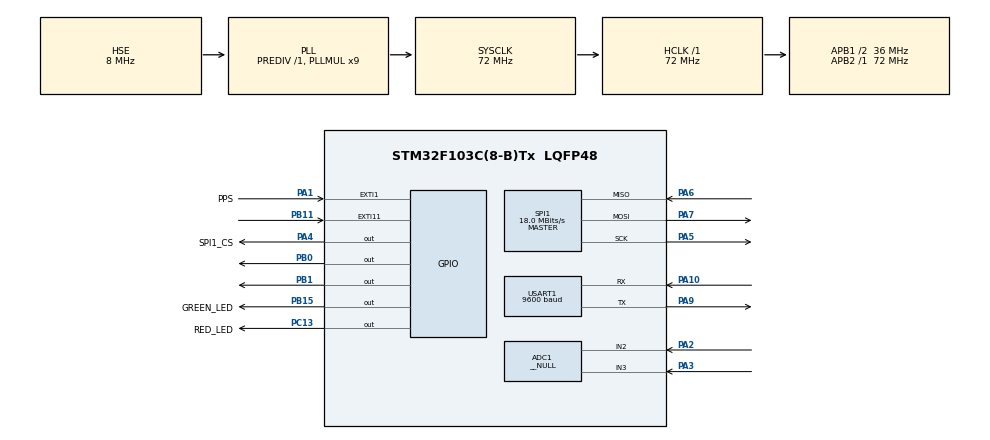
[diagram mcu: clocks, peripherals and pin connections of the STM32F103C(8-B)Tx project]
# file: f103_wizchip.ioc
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ADC1.Channel-0\#ChannelRegularConversion=ADC_CHANNEL_2
ADC1.ContinuousConvMode=DISABLE
ADC1.ExternalTrigConv=ADC_EXTERNALTRIGCONV_EXT_IT11
ADC1.InjNumberOfConversion=0
ADC1.Mode=__NULL
ADC1.NbrOfConversion=1
ADC1.NbrOfConversionFlag=1
ADC1.Rank-0\#ChannelRegularConversion=1
ADC1.SamplingTime-0\#ChannelRegularConversion=ADC_SAMPLETIME_1CYCLE_5
ADC1.master=1
ADC2.Channel-0\#ChannelRegularConversion=ADC_CHANNEL_3
ADC2.NbrOfConversionFlag=1
ADC2.Rank-0\#ChannelRegularConversion=1
ADC2.SamplingTime-0\#ChannelRegularConversion=ADC_SAMPLETIME_1CYCLE_5
Dma.ADC1.0.Direction=DMA_PERIPH_TO_MEMORY
Dma.ADC1.0.Instance=DMA1_Channel1
Dma.ADC1.0.MemDataAlignment=DMA_MDATAALIGN_HALFWORD
Dma.ADC1.0.MemInc=DMA_MINC_ENABLE
Dma.ADC1.0.Mode=DMA_CIRCULAR
Dma.ADC1.0.PeriphDataAlignment=DMA_PDATAALIGN_HALFWORD
Dma.ADC1.0.PeriphInc=DMA_PINC_DISABLE
Dma.ADC1.0.Priority=DMA_PRIORITY_VERY_HIGH
Dma.Request0=ADC1
Mcu.Family=STM32F1
Mcu.Name=STM32F103C(8-B)Tx
Mcu.Package=LQFP48
NVIC.DMA1_Channel1_IRQn=true\:0\:0\:false\:false\:true\:false
NVIC.EXTI1_IRQn=true\:0\:0\:false\:false\:true\:true
NVIC.PriorityGroup=NVIC_PRIORITYGROUP_4
PA1.GPIO_Label=PPS
PA1.GPIO_ModeDefaultEXTI=GPIO_MODE_IT_RISING
PA1.GPIO_PuPd=GPIO_NOPULL
PA1.Signal=GPXTI1
PA10.Mode=Asynchronous
PA10.Signal=USART1_RX
PA13.Mode=Serial_Wire
PA13.Signal=SYS_JTMS-SWDIO
PA14.Mode=Serial_Wire
PA14.Signal=SYS_JTCK-SWCLK
PA2.Signal=ADCx_IN2
PA3.Signal=ADCx_IN3
PA4.GPIO_Label=SPI1_CS
PA4.Signal=GPIO_Output
PA5.Mode=Full_Duplex_Master
PA5.Signal=SPI1_SCK
PA6.Mode=Full_Duplex_Master
PA6.Signal=SPI1_MISO
PA7.Mode=Full_Duplex_Master
PA7.Signal=SPI1_MOSI
PA9.Mode=Asynchronous
PA9.Signal=USART1_TX
PB0.Signal=GPIO_Output
PB1.Signal=GPIO_Output
PB11.Signal=GPXTI11
PB15.GPIO_Label=GREEN_LED
PB15.Signal=GPIO_Output
PC13-TAMPER-RTC.GPIO_Label=RED_LED
PC13-TAMPER-RTC.Signal=GPIO_Output
PC14-OSC32_IN.Mode=LSE-External-Oscillator
PC14-OSC32_IN.Signal=RCC_OSC32_IN
PC15-OSC32_OUT.Mode=LSE-External-Oscillator
PC15-OSC32_OUT.Signal=RCC_OSC32_OUT
PD0-OSC_IN.Mode=HSE-External-Oscillator
PD0-OSC_IN.Signal=RCC_OSC_IN
PD1-OSC_OUT.Mode=HSE-External-Oscillator
PD1-OSC_OUT.Signal=RCC_OSC_OUT
ProjectManager.HeapSize=0x200
ProjectManager.StackSize=0x400
ProjectManager.TargetToolchain=TrueSTUDIO
RCC.ADCPresc=RCC_ADCPCLK2_DIV8
RCC.AHBFreq_Value=72000000
RCC.APB1CLKDivider=RCC_HCLK_DIV2
RCC.APB1Freq_Value=36000000
RCC.APB1TimFreq_Value=72000000
RCC.APB2Freq_Value=72000000
RCC.APB2TimFreq_Value=72000000
RCC.HCLKFreq_Value=72000000
RCC.PLLMUL=RCC_PLL_MUL9
RCC.PLLSourceVirtual=RCC_PLLSOURCE_HSE
RCC.RCC_MCOSource=RCC_MCO1SOURCE_PLLCLK
RCC.SYSCLKFreq_VALUE=72000000
RCC.SYSCLKSource=RCC_SYSCLKSOURCE_PLLCLK
RCC.USBFreq_Value=72000000
SH.ADCx_IN2.0=ADC1_IN2,IN2
SH.ADCx_IN3.0=ADC1_IN3,IN3
SH.ADCx_IN3.1=ADC2_IN3,IN3
SPI1.BaudRatePrescaler=SPI_BAUDRATEPRESCALER_4
SPI1.CalculateBaudRate=18.0 MBits/s
SPI1.Direction=SPI_DIRECTION_2LINES
SPI1.FirstBit=SPI_FIRSTBIT_MSB
SPI1.Mode=SPI_MODE_MASTER
SPI1.VirtualType=VM_MASTER
TIM3.Period=35999
TIM3.Prescaler=1
TIM3.TIM_MasterOutputTrigger=TIM_TRGO_UPDATE
USART1.BaudRate=9600
USART1.VirtualMode=VM_ASYNC
VP_TIM3_VS_ClockSourceINT.Mode=Internal
board=custom

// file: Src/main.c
/* USER CODE BEGIN Header */
/**
  ******************************************************************************
  * @file           : main.c
  * @brief          : Main program body
  ******************************************************************************
  ** This notice applies to any and all portions of this file
  * that are not between comment pairs USER CODE BEGIN and
  * USER CODE END. Other portions of this file, whether
  * inserted by the user or by software development tools
  * are owned by their respective copyright owners.
  *
  * COPYRIGHT(c) 2020 STMicroelectronics
  *
  * Redistribution and use in source and binary forms, with or without modification,
  * are permitted provided that the following conditions are met:
  *   1. Redistributions of source code must retain the above copyright notice,
  *      this list of conditions and the following disclaimer.
  *   2. Redistributions in binary form must reproduce the above copyright notice,
  *      this list of conditions and the following disclaimer in the documentation
  *      and/or other materials provided with the distribution.
  *   3. Neither the name of STMicroelectronics nor the names of its contributors
  *      may be used to endorse or promote products derived from this software
  *      without specific prior written permission.
  *
  * THIS SOFTWARE IS PROVIDED BY THE COPYRIGHT HOLDERS AND CONTRIBUTORS "AS IS"
  * AND ANY EXPRESS OR IMPLIED WARRANTIES, INCLUDING, BUT NOT LIMITED TO, THE
  * IMPLIED WARRANTIES OF MERCHANTABILITY AND FITNESS FOR A PARTICULAR PURPOSE ARE
  * DISCLAIMED. IN NO EVENT SHALL THE COPYRIGHT HOLDER OR CONTRIBUTORS BE LIABLE
  * FOR ANY DIRECT, INDIRECT, INCIDENTAL, SPECIAL, EXEMPLARY, OR CONSEQUENTIAL
  * DAMAGES (INCLUDING, BUT NOT LIMITED TO, PROCUREMENT OF SUBSTITUTE GOODS OR
  * SERVICES; LOSS OF USE, DATA, OR PROFITS; OR BUSINESS INTERRUPTION) HOWEVER
  * CAUSED AND ON ANY THEORY OF LIABILITY, WHETHER IN CONTRACT, STRICT LIABILITY,
  * OR TORT (INCLUDING NEGLIGENCE OR OTHERWISE) ARISING IN ANY WAY OUT OF THE USE
  * OF THIS SOFTWARE, EVEN IF ADVISED OF THE POSSIBILITY OF SUCH DAMAGE.
  *
  ******************************************************************************
  */
/* USER CODE END Header */

#include "main.h"

/* USER CODE BEGIN Includes */
#include "stm32f1xx_hal_gpio.h"
#include "wizchip_init.h"
#include "write_flash.h"
/* USER CODE END Includes */

ADC_HandleTypeDef hadc1;
ADC_HandleTypeDef hadc2;
DMA_HandleTypeDef hdma_adc1;

SPI_HandleTypeDef hspi1;

TIM_HandleTypeDef htim3;

UART_HandleTypeDef huart1;

void SystemClock_Config(void);
static void MX_GPIO_Init(void);
static void MX_DMA_Init(void);
static void MX_SPI1_Init(void);
static void MX_ADC1_Init(void);
static void MX_USART1_UART_Init(void);
static void MX_TIM3_Init(void);
static void MX_ADC2_Init(void);
/* USER CODE BEGIN PFP */
void Config_RCC(void);  //Тут меняем RCC
/* USER CODE END PFP */

/* USER CODE BEGIN 0 */
void WizchIP_main(SPI_HandleTypeDef* spi, UART_HandleTypeDef* uart, ADC_HandleTypeDef* adc);

/* USER CODE END 0 */

int main(void)
{

  /* MCU Configuration--------------------------------------------------------*/

  /* Reset of all peripherals, Initializes the Flash interface and the Systick. */
  HAL_Init();

  /* Configure the system clock */
  SystemClock_Config();

  /* Initialize all configured peripherals */
  MX_GPIO_Init();
  MX_DMA_Init();
  MX_SPI1_Init();
  MX_ADC1_Init();
  MX_USART1_UART_Init();
  MX_TIM3_Init();
  MX_ADC2_Init();
  /* USER CODE BEGIN 2 */

  //config_rcc();

 WizchIP_main(&hspi1, &huart1, &hadc1);		// HUART1 вкл, чтобы весь код не перебирать

  /* USER CODE END 2 */

  /* Infinite loop */
  while (1)
  {

  }
}

void SystemClock_Config(void)
{
  RCC_OscInitTypeDef RCC_OscInitStruct = {0};
  RCC_ClkInitTypeDef RCC_ClkInitStruct = {0};
  RCC_PeriphCLKInitTypeDef PeriphClkInit = {0};

  /**Initializes the CPU, AHB and APB busses clocks
  */
  RCC_OscInitStruct.OscillatorType = RCC_OSCILLATORTYPE_HSE;
  RCC_OscInitStruct.HSEState = RCC_HSE_ON;
  RCC_OscInitStruct.HSEPredivValue = RCC_HSE_PREDIV_DIV1;
  RCC_OscInitStruct.HSIState = RCC_HSI_ON;
  RCC_OscInitStruct.PLL.PLLState = RCC_PLL_ON;
  RCC_OscInitStruct.PLL.PLLSource = RCC_PLLSOURCE_HSE;
  RCC_OscInitStruct.PLL.PLLMUL = RCC_PLL_MUL9;
  if (HAL_RCC_OscConfig(&RCC_OscInitStruct) != HAL_OK)
  {
    Error_Handler();
  }
  /**Initializes the CPU, AHB and APB busses clocks
  */
  RCC_ClkInitStruct.ClockType = RCC_CLOCKTYPE_HCLK|RCC_CLOCKTYPE_SYSCLK
                              |RCC_CLOCKTYPE_PCLK1|RCC_CLOCKTYPE_PCLK2;
  RCC_ClkInitStruct.SYSCLKSource = RCC_SYSCLKSOURCE_PLLCLK;
  RCC_ClkInitStruct.AHBCLKDivider = RCC_SYSCLK_DIV1;
  RCC_ClkInitStruct.APB1CLKDivider = RCC_HCLK_DIV2;
  RCC_ClkInitStruct.APB2CLKDivider = RCC_HCLK_DIV1;

  if (HAL_RCC_ClockConfig(&RCC_ClkInitStruct, FLASH_LATENCY_2) != HAL_OK)
  {
    Error_Handler();
  }
  PeriphClkInit.PeriphClockSelection = RCC_PERIPHCLK_ADC;
  PeriphClkInit.AdcClockSelection = RCC_ADCPCLK2_DIV8;
  if (HAL_RCCEx_PeriphCLKConfig(&PeriphClkInit) != HAL_OK)
  {
    Error_Handler();
  }
}

static void MX_ADC1_Init(void)
{

  ADC_ChannelConfTypeDef sConfig = {0};

  /**Common config
  */
  hadc1.Instance = ADC1;
  hadc1.Init.ScanConvMode = ADC_SCAN_DISABLE;
  hadc1.Init.ContinuousConvMode = DISABLE;
  hadc1.Init.DiscontinuousConvMode = DISABLE;
  hadc1.Init.ExternalTrigConv = ADC_EXTERNALTRIGCONV_EXT_IT11;
  hadc1.Init.DataAlign = ADC_DATAALIGN_RIGHT;
  hadc1.Init.NbrOfConversion = 1;
  if (HAL_ADC_Init(&hadc1) != HAL_OK)
  {
    Error_Handler();
  }
  /**Configure Regular Channel
  */
  sConfig.Channel = ADC_CHANNEL_2;
  sConfig.Rank = ADC_REGULAR_RANK_1;
  sConfig.SamplingTime = ADC_SAMPLETIME_1CYCLE_5;
  if (HAL_ADC_ConfigChannel(&hadc1, &sConfig) != HAL_OK)
  {
    Error_Handler();
  }

}

static void MX_ADC2_Init(void)
{

  ADC_ChannelConfTypeDef sConfig = {0};

  /**Common config
  */
  hadc2.Instance = ADC2;
  hadc2.Init.ScanConvMode = ADC_SCAN_DISABLE;
  hadc2.Init.ContinuousConvMode = DISABLE;
  hadc2.Init.DiscontinuousConvMode = DISABLE;
  hadc2.Init.ExternalTrigConv = ADC_SOFTWARE_START;
  hadc2.Init.DataAlign = ADC_DATAALIGN_RIGHT;
  hadc2.Init.NbrOfConversion = 1;
  if (HAL_ADC_Init(&hadc2) != HAL_OK)
  {
    Error_Handler();
  }
  /**Configure Regular Channel
  */
  sConfig.Channel = ADC_CHANNEL_3;
  sConfig.Rank = ADC_REGULAR_RANK_1;
  sConfig.SamplingTime = ADC_SAMPLETIME_1CYCLE_5;
  if (HAL_ADC_ConfigChannel(&hadc2, &sConfig) != HAL_OK)
  {
    Error_Handler();
  }

}

static void MX_SPI1_Init(void)
{

  /* SPI1 parameter configuration*/
  hspi1.Instance = SPI1;
  hspi1.Init.Mode = SPI_MODE_MASTER;
  hspi1.Init.Direction = SPI_DIRECTION_2LINES;
  hspi1.Init.DataSize = SPI_DATASIZE_8BIT;
  hspi1.Init.CLKPolarity = SPI_POLARITY_LOW;
  hspi1.Init.CLKPhase = SPI_PHASE_1EDGE;
  hspi1.Init.NSS = SPI_NSS_SOFT;
  hspi1.Init.BaudRatePrescaler = SPI_BAUDRATEPRESCALER_4;
  hspi1.Init.FirstBit = SPI_FIRSTBIT_MSB;
  hspi1.Init.TIMode = SPI_TIMODE_DISABLE;
  hspi1.Init.CRCCalculation = SPI_CRCCALCULATION_DISABLE;
  hspi1.Init.CRCPolynomial = 10;
  if (HAL_SPI_Init(&hspi1) != HAL_OK)
  {
    Error_Handler();
  }

}

static void MX_TIM3_Init(void)
{

  TIM_ClockConfigTypeDef sClockSourceConfig = {0};
  TIM_MasterConfigTypeDef sMasterConfig = {0};

  htim3.Instance = TIM3;
  htim3.Init.Prescaler = 1;
  htim3.Init.CounterMode = TIM_COUNTERMODE_UP;
  htim3.Init.Period = 35999;
  htim3.Init.ClockDivision = TIM_CLOCKDIVISION_DIV1;
  htim3.Init.AutoReloadPreload = TIM_AUTORELOAD_PRELOAD_DISABLE;
  if (HAL_TIM_Base_Init(&htim3) != HAL_OK)
  {
    Error_Handler();
  }
  sClockSourceConfig.ClockSource = TIM_CLOCKSOURCE_INTERNAL;
  if (HAL_TIM_ConfigClockSource(&htim3, &sClockSourceConfig) != HAL_OK)
  {
    Error_Handler();
  }
  sMasterConfig.MasterOutputTrigger = TIM_TRGO_UPDATE;
  sMasterConfig.MasterSlaveMode = TIM_MASTERSLAVEMODE_DISABLE;
  if (HAL_TIMEx_MasterConfigSynchronization(&htim3, &sMasterConfig) != HAL_OK)
  {
    Error_Handler();
  }

}

static void MX_USART1_UART_Init(void)
{

  huart1.Instance = USART1;
  huart1.Init.BaudRate = 9600;
  huart1.Init.WordLength = UART_WORDLENGTH_8B;
  huart1.Init.StopBits = UART_STOPBITS_1;
  huart1.Init.Parity = UART_PARITY_NONE;
  huart1.Init.Mode = UART_MODE_TX_RX;
  huart1.Init.HwFlowCtl = UART_HWCONTROL_NONE;
  huart1.Init.OverSampling = UART_OVERSAMPLING_16;
  if (HAL_UART_Init(&huart1) != HAL_OK)
  {
    Error_Handler();
  }

}

static void MX_DMA_Init(void)
{
  /* DMA controller clock enable */
  __HAL_RCC_DMA1_CLK_ENABLE();

  /* DMA interrupt init */
  /* DMA1_Channel1_IRQn interrupt configuration */
  HAL_NVIC_SetPriority(DMA1_Channel1_IRQn, 0, 0);
  HAL_NVIC_EnableIRQ(DMA1_Channel1_IRQn);

}

static void MX_GPIO_Init(void)
{
  GPIO_InitTypeDef GPIO_InitStruct = {0};

  /* GPIO Ports Clock Enable */
  __HAL_RCC_GPIOC_CLK_ENABLE();
  __HAL_RCC_GPIOD_CLK_ENABLE();
  __HAL_RCC_GPIOA_CLK_ENABLE();
  __HAL_RCC_GPIOB_CLK_ENABLE();

  /*Configure GPIO pin Output Level */
  HAL_GPIO_WritePin(RED_LED_GPIO_Port, RED_LED_Pin, GPIO_PIN_RESET);

  /*Configure GPIO pin Output Level */
  HAL_GPIO_WritePin(SPI1_CS_GPIO_Port, SPI1_CS_Pin, GPIO_PIN_RESET);

  /*Configure GPIO pin Output Level */
  HAL_GPIO_WritePin(GPIOB, GPIO_PIN_0|GPIO_PIN_1|GREEN_LED_Pin, GPIO_PIN_RESET);

  /*Configure GPIO pin : RED_LED_Pin */
  GPIO_InitStruct.Pin = RED_LED_Pin;
  GPIO_InitStruct.Mode = GPIO_MODE_OUTPUT_PP;
  GPIO_InitStruct.Pull = GPIO_NOPULL;
  GPIO_InitStruct.Speed = GPIO_SPEED_FREQ_LOW;
  HAL_GPIO_Init(RED_LED_GPIO_Port, &GPIO_InitStruct);

  /*Configure GPIO pin : PPS_Pin */
  GPIO_InitStruct.Pin = PPS_Pin;
  GPIO_InitStruct.Mode = GPIO_MODE_IT_RISING;
  GPIO_InitStruct.Pull = GPIO_NOPULL;
  HAL_GPIO_Init(PPS_GPIO_Port, &GPIO_InitStruct);

  /*Configure GPIO pin : SPI1_CS_Pin */
  GPIO_InitStruct.Pin = SPI1_CS_Pin;
  GPIO_InitStruct.Mode = GPIO_MODE_OUTPUT_PP;
  GPIO_InitStruct.Pull = GPIO_NOPULL;
  GPIO_InitStruct.Speed = GPIO_SPEED_FREQ_LOW;
  HAL_GPIO_Init(SPI1_CS_GPIO_Port, &GPIO_InitStruct);

  /*Configure GPIO pins : PB0 PB1 GREEN_LED_Pin */
  GPIO_InitStruct.Pin = GPIO_PIN_0|GPIO_PIN_1|GREEN_LED_Pin;
  GPIO_InitStruct.Mode = GPIO_MODE_OUTPUT_PP;
  GPIO_InitStruct.Pull = GPIO_NOPULL;
  GPIO_InitStruct.Speed = GPIO_SPEED_FREQ_LOW;
  HAL_GPIO_Init(GPIOB, &GPIO_InitStruct);

  /*Configure GPIO pin : PB11 */
  GPIO_InitStruct.Pin = GPIO_PIN_11;
  GPIO_InitStruct.Mode = GPIO_MODE_IT_RISING;
  GPIO_InitStruct.Pull = GPIO_NOPULL;
  HAL_GPIO_Init(GPIOB, &GPIO_InitStruct);

  /* EXTI interrupt init*/
  HAL_NVIC_SetPriority(EXTI1_IRQn, 0, 0);
  HAL_NVIC_EnableIRQ(EXTI1_IRQn);

}

void Error_Handler(void)
{
}

/************************ (C) COPYRIGHT STMicroelectronics *****END OF FILE****/
